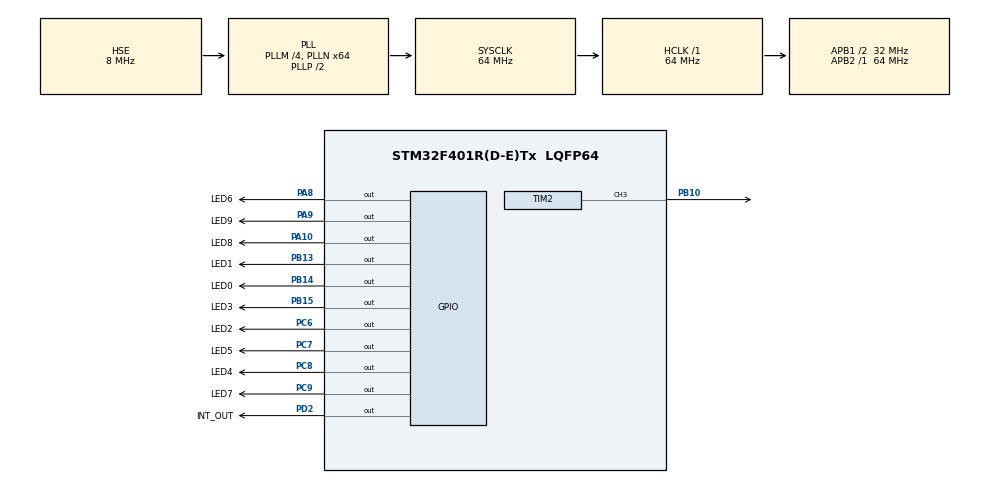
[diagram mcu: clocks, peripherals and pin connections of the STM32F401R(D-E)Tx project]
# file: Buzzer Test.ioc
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FREERTOS.Tasks01=StateMachine,8,128,doStateMachine,Default,NULL,Dynamic,NULL,NULL
FREERTOS.configENABLE_FPU=1
FREERTOS.configRECORD_STACK_HIGH_ADDRESS=1
Mcu.Family=STM32F4
Mcu.Name=STM32F401R(D-E)Tx
Mcu.Package=LQFP64
NVIC.PriorityGroup=NVIC_PRIORITYGROUP_4
NVIC.TIM5_IRQn=true\:0\:0\:false\:false\:true\:false\:false\:true
NVIC.TimeBase=TIM5_IRQn
NVIC.TimeBaseIP=TIM5
PA10.GPIO_Label=LED8
PA10.Signal=GPIO_Output
PA8.GPIO_Label=LED6
PA8.Signal=GPIO_Output
PA9.GPIO_Label=LED9
PA9.Signal=GPIO_Output
PB10.Signal=S_TIM2_CH3
PB13.GPIO_Label=LED1
PB13.Signal=GPIO_Output
PB14.GPIO_Label=LED0
PB14.Signal=GPIO_Output
PB15.GPIO_Label=LED3
PB15.Signal=GPIO_Output
PC6.GPIO_Label=LED2
PC6.Signal=GPIO_Output
PC7.GPIO_Label=LED5
PC7.Signal=GPIO_Output
PC8.GPIO_Label=LED4
PC8.Signal=GPIO_Output
PC9.GPIO_Label=LED7
PC9.Signal=GPIO_Output
PD2.GPIO_Label=INT_OUT
PD2.Signal=GPIO_Output
PH0\ -\ OSC_IN.Mode=HSE-External-Clock-Source
PH0\ -\ OSC_IN.Signal=RCC_OSC_IN
PH1\ -\ OSC_OUT.Mode=HSE-External-Clock-Source
PH1\ -\ OSC_OUT.Signal=RCC_OSC_OUT
ProjectManager.HeapSize=0x200
ProjectManager.StackSize=0x800
ProjectManager.TargetToolchain=STM32CubeIDE
RCC.48MHZClocksFreq_Value=32000000
RCC.AHBFreq_Value=64000000
RCC.APB1CLKDivider=RCC_HCLK_DIV2
RCC.APB1Freq_Value=32000000
RCC.APB1TimFreq_Value=64000000
RCC.APB2Freq_Value=64000000
RCC.APB2TimFreq_Value=64000000
RCC.CortexFreq_Value=64000000
RCC.HCLKFreq_Value=64000000
RCC.HSE_VALUE=8000000
RCC.HSI_VALUE=16000000
RCC.LSE_VALUE=32768
RCC.PLLM=4
RCC.PLLN=64
RCC.PLLSourceVirtual=RCC_PLLSOURCE_HSE
RCC.SYSCLKFreq_VALUE=64000000
RCC.SYSCLKSource=RCC_SYSCLKSOURCE_PLLCLK
RCC.VCOOutputFreq_Value=128000000
SH.S_TIM2_CH3.0=TIM2_CH3,Output Compare3 CH3
TIM2.Channel-Output\ Compare3\ CH3=TIM_CHANNEL_3
TIM2.OCMode_3=TIM_OCMODE_TOGGLE
TIM2.Period=1000
TIM2.Prescaler=64
VP_FREERTOS_VS_CMSIS_V2.Mode=CMSIS_V2
VP_SYS_VS_tim5.Mode=TIM5
VP_TIM2_VS_ClockSourceINT.Mode=Internal
board=custom

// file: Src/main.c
/* USER CODE BEGIN Header */
/**
  ******************************************************************************
  * @file           : main.c
  * @brief          : Main program body
  ******************************************************************************
  * @attention
  *
  * <h2><center>&copy; Copyright (c) 2020 STMicroelectronics.
  * All rights reserved.</center></h2>
  *
  * This software component is licensed by ST under BSD 3-Clause license,
  * the "License"; You may not use this file except in compliance with the
  * License. You may obtain a copy of the License at:
  *                        opensource.org/licenses/BSD-3-Clause
  *
  ******************************************************************************
  */
/* USER CODE END Header */
#include "main.h"
#include "cmsis_os.h"

/* USER CODE BEGIN Includes */
#include "bargraph.h"
#include "state_machine.h"
/* USER CODE END Includes */

TIM_HandleTypeDef htim2;

/* Definitions for StateMachine */
osThreadId_t StateMachineHandle;
const osThreadAttr_t StateMachine_attributes = {
  .name = "StateMachine",
  .priority = (osPriority_t) osPriorityLow,
  .stack_size = 128 * 4
};
/* USER CODE BEGIN PV */
extern TIM_HandleTypeDef htim5; //weird that this doesn't get thrown in by default

/* USER CODE END PV */

void SystemClock_Config(void);
static void MX_GPIO_Init(void);
static void MX_TIM2_Init(void);
void doStateMachine(void *argument);

int main(void)
{

  /* MCU Configuration--------------------------------------------------------*/

  /* Reset of all peripherals, Initializes the Flash interface and the Systick. */
	HAL_Init();

  /* Configure the system clock */
  SystemClock_Config();

  /* Initialize all configured peripherals */
  MX_GPIO_Init();
  MX_TIM2_Init();
  /* USER CODE BEGIN 2 */
  HAL_TIM_Base_Start_IT(&htim5);
  /* USER CODE END 2 */

  /* Init scheduler */
  osKernelInitialize();

  /* Create the thread(s) */
  /* creation of StateMachine */
  StateMachineHandle = osThreadNew(doStateMachine, NULL, &StateMachine_attributes);

  /* Start scheduler */
  osKernelStart();

  /* We should never get here as control is now taken by the scheduler */
  /* Infinite loop */
  /* USER CODE BEGIN WHILE */
  while (1)
  {
	  //should never actually reach here I think
    /* USER CODE END WHILE */

  }
}

void SystemClock_Config(void)
{
  RCC_OscInitTypeDef RCC_OscInitStruct = {0};
  RCC_ClkInitTypeDef RCC_ClkInitStruct = {0};

  /** Configure the main internal regulator output voltage
  */
  __HAL_RCC_PWR_CLK_ENABLE();
  __HAL_PWR_VOLTAGESCALING_CONFIG(PWR_REGULATOR_VOLTAGE_SCALE2);
  /** Initializes the RCC Oscillators according to the specified parameters
  * in the RCC_OscInitTypeDef structure.
  */
  RCC_OscInitStruct.OscillatorType = RCC_OSCILLATORTYPE_HSE;
  RCC_OscInitStruct.HSEState = RCC_HSE_BYPASS;
  RCC_OscInitStruct.PLL.PLLState = RCC_PLL_ON;
  RCC_OscInitStruct.PLL.PLLSource = RCC_PLLSOURCE_HSE;
  RCC_OscInitStruct.PLL.PLLM = 4;
  RCC_OscInitStruct.PLL.PLLN = 64;
  RCC_OscInitStruct.PLL.PLLP = RCC_PLLP_DIV2;
  RCC_OscInitStruct.PLL.PLLQ = 4;
  if (HAL_RCC_OscConfig(&RCC_OscInitStruct) != HAL_OK)
  {
    Error_Handler();
  }
  /** Initializes the CPU, AHB and APB buses clocks
  */
  RCC_ClkInitStruct.ClockType = RCC_CLOCKTYPE_HCLK|RCC_CLOCKTYPE_SYSCLK
                              |RCC_CLOCKTYPE_PCLK1|RCC_CLOCKTYPE_PCLK2;
  RCC_ClkInitStruct.SYSCLKSource = RCC_SYSCLKSOURCE_PLLCLK;
  RCC_ClkInitStruct.AHBCLKDivider = RCC_SYSCLK_DIV1;
  RCC_ClkInitStruct.APB1CLKDivider = RCC_HCLK_DIV2;
  RCC_ClkInitStruct.APB2CLKDivider = RCC_HCLK_DIV1;

  if (HAL_RCC_ClockConfig(&RCC_ClkInitStruct, FLASH_LATENCY_2) != HAL_OK)
  {
    Error_Handler();
  }
}

static void MX_TIM2_Init(void)
{

  TIM_ClockConfigTypeDef sClockSourceConfig = {0};
  TIM_MasterConfigTypeDef sMasterConfig = {0};
  TIM_OC_InitTypeDef sConfigOC = {0};

  htim2.Instance = TIM2;
  htim2.Init.Prescaler = 64;
  htim2.Init.CounterMode = TIM_COUNTERMODE_UP;
  htim2.Init.Period = 1000;
  htim2.Init.ClockDivision = TIM_CLOCKDIVISION_DIV1;
  htim2.Init.AutoReloadPreload = TIM_AUTORELOAD_PRELOAD_DISABLE;
  if (HAL_TIM_Base_Init(&htim2) != HAL_OK)
  {
    Error_Handler();
  }
  sClockSourceConfig.ClockSource = TIM_CLOCKSOURCE_INTERNAL;
  if (HAL_TIM_ConfigClockSource(&htim2, &sClockSourceConfig) != HAL_OK)
  {
    Error_Handler();
  }
  if (HAL_TIM_OC_Init(&htim2) != HAL_OK)
  {
    Error_Handler();
  }
  sMasterConfig.MasterOutputTrigger = TIM_TRGO_RESET;
  sMasterConfig.MasterSlaveMode = TIM_MASTERSLAVEMODE_DISABLE;
  if (HAL_TIMEx_MasterConfigSynchronization(&htim2, &sMasterConfig) != HAL_OK)
  {
    Error_Handler();
  }
  sConfigOC.OCMode = TIM_OCMODE_TOGGLE;
  sConfigOC.Pulse = 0;
  sConfigOC.OCPolarity = TIM_OCPOLARITY_HIGH;
  sConfigOC.OCFastMode = TIM_OCFAST_DISABLE;
  if (HAL_TIM_OC_ConfigChannel(&htim2, &sConfigOC, TIM_CHANNEL_3) != HAL_OK)
  {
    Error_Handler();
  }
  HAL_TIM_MspPostInit(&htim2);

}

static void MX_GPIO_Init(void)
{
  GPIO_InitTypeDef GPIO_InitStruct = {0};

  /* GPIO Ports Clock Enable */
  __HAL_RCC_GPIOH_CLK_ENABLE();
  __HAL_RCC_GPIOB_CLK_ENABLE();
  __HAL_RCC_GPIOC_CLK_ENABLE();
  __HAL_RCC_GPIOA_CLK_ENABLE();
  __HAL_RCC_GPIOD_CLK_ENABLE();

  /*Configure GPIO pin Output Level */
  HAL_GPIO_WritePin(GPIOB, LED1_Pin|LED0_Pin|LED3_Pin, GPIO_PIN_RESET);

  /*Configure GPIO pin Output Level */
  HAL_GPIO_WritePin(GPIOC, LED2_Pin|LED5_Pin|LED4_Pin|LED7_Pin, GPIO_PIN_RESET);

  /*Configure GPIO pin Output Level */
  HAL_GPIO_WritePin(GPIOA, LED6_Pin|LED9_Pin|LED8_Pin, GPIO_PIN_RESET);

  /*Configure GPIO pin Output Level */
  HAL_GPIO_WritePin(INT_OUT_GPIO_Port, INT_OUT_Pin, GPIO_PIN_RESET);

  /*Configure GPIO pins : LED1_Pin LED0_Pin LED3_Pin */
  GPIO_InitStruct.Pin = LED1_Pin|LED0_Pin|LED3_Pin;
  GPIO_InitStruct.Mode = GPIO_MODE_OUTPUT_PP;
  GPIO_InitStruct.Pull = GPIO_NOPULL;
  GPIO_InitStruct.Speed = GPIO_SPEED_FREQ_LOW;
  HAL_GPIO_Init(GPIOB, &GPIO_InitStruct);

  /*Configure GPIO pins : LED2_Pin LED5_Pin LED4_Pin LED7_Pin */
  GPIO_InitStruct.Pin = LED2_Pin|LED5_Pin|LED4_Pin|LED7_Pin;
  GPIO_InitStruct.Mode = GPIO_MODE_OUTPUT_PP;
  GPIO_InitStruct.Pull = GPIO_NOPULL;
  GPIO_InitStruct.Speed = GPIO_SPEED_FREQ_LOW;
  HAL_GPIO_Init(GPIOC, &GPIO_InitStruct);

  /*Configure GPIO pins : LED6_Pin LED9_Pin LED8_Pin */
  GPIO_InitStruct.Pin = LED6_Pin|LED9_Pin|LED8_Pin;
  GPIO_InitStruct.Mode = GPIO_MODE_OUTPUT_PP;
  GPIO_InitStruct.Pull = GPIO_NOPULL;
  GPIO_InitStruct.Speed = GPIO_SPEED_FREQ_LOW;
  HAL_GPIO_Init(GPIOA, &GPIO_InitStruct);

  /*Configure GPIO pin : INT_OUT_Pin */
  GPIO_InitStruct.Pin = INT_OUT_Pin;
  GPIO_InitStruct.Mode = GPIO_MODE_OUTPUT_PP;
  GPIO_InitStruct.Pull = GPIO_NOPULL;
  GPIO_InitStruct.Speed = GPIO_SPEED_FREQ_LOW;
  HAL_GPIO_Init(INT_OUT_GPIO_Port, &GPIO_InitStruct);

}

void HAL_TIM_PeriodElapsedCallback(TIM_HandleTypeDef *htim)
{
  if (htim->Instance == TIM5) {
    HAL_IncTick();
  }
}

void Error_Handler(void)
{
}

/************************ (C) COPYRIGHT STMicroelectronics *****END OF FILE****/
